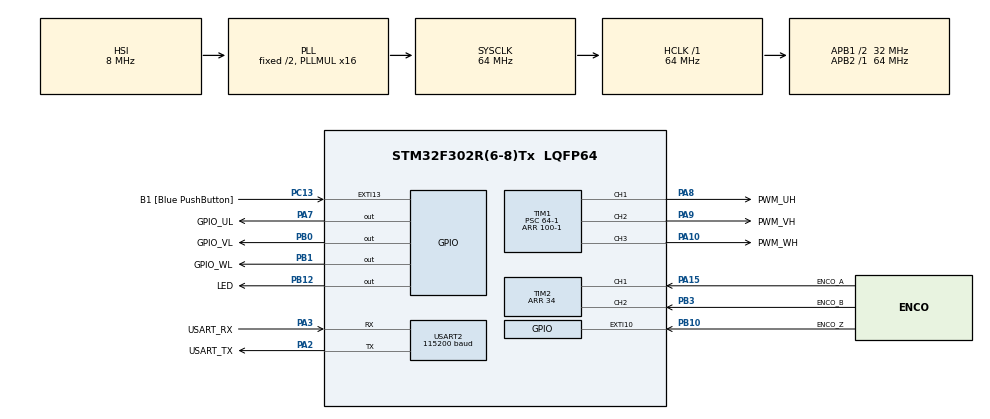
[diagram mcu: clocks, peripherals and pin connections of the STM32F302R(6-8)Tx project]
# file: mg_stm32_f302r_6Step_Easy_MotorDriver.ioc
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Mcu.Family=STM32F3
Mcu.Name=STM32F302R(6-8)Tx
Mcu.Package=LQFP64
NVIC.EXTI15_10_IRQn=true\:0\:0\:false\:false\:true\:true\:true\:true
NVIC.PriorityGroup=NVIC_PRIORITYGROUP_0
NVIC.TIM2_IRQn=true\:0\:0\:false\:false\:true\:true\:true\:true
NVIC.USART2_IRQn=true\:0\:0\:false\:false\:true\:true\:true\:true
PA10.GPIO_Label=PWM_WH
PA10.Signal=S_TIM1_CH3
PA13.GPIO_Label=TMS
PA13.Signal=SYS_JTMS-SWDIO
PA14.GPIO_Label=TCK
PA14.Signal=SYS_JTCK-SWCLK
PA15.GPIO_Label=ENCO_A
PA15.Signal=S_TIM2_CH1_ETR
PA2.GPIO_Label=USART_TX
PA2.GPIO_Mode=GPIO_MODE_AF_PP
PA2.GPIO_PuPd=GPIO_NOPULL
PA2.GPIO_Speed=GPIO_SPEED_FREQ_LOW
PA2.Mode=Asynchronous
PA2.Signal=USART2_TX
PA3.GPIO_Label=USART_RX
PA3.GPIO_Mode=GPIO_MODE_AF_PP
PA3.GPIO_PuPd=GPIO_NOPULL
PA3.GPIO_Speed=GPIO_SPEED_FREQ_LOW
PA3.Mode=Asynchronous
PA3.Signal=USART2_RX
PA7.GPIO_Label=GPIO_UL
PA7.Signal=GPIO_Output
PA8.GPIO_Label=PWM_UH
PA8.Signal=S_TIM1_CH1
PA9.GPIO_Label=PWM_VH
PA9.Signal=S_TIM1_CH2
PB0.GPIO_Label=GPIO_VL
PB0.Signal=GPIO_Output
PB1.GPIO_Label=GPIO_WL
PB1.Signal=GPIO_Output
PB10.GPIO_Label=ENCO_Z
PB10.Signal=GPXTI10
PB12.GPIO_Label=LED
PB12.Signal=GPIO_Output
PB3.GPIO_Label=ENCO_B
PB3.Signal=S_TIM2_CH2
PC13.GPIO_Label=B1 [Blue PushButton]
PC13.GPIO_ModeDefaultEXTI=GPIO_MODE_IT_FALLING
PC13.Signal=GPXTI13
ProjectManager.HeapSize=0x200
ProjectManager.StackSize=0x400
ProjectManager.TargetToolchain=STM32CubeIDE
RCC.AHBFreq_Value=64000000
RCC.APB1CLKDivider=RCC_HCLK_DIV2
RCC.APB1Freq_Value=32000000
RCC.APB1TimFreq_Value=64000000
RCC.APB2Freq_Value=64000000
RCC.APB2TimFreq_Value=64000000
RCC.CortexFreq_Value=64000000
RCC.HCLKFreq_Value=64000000
RCC.HSE_VALUE=8000000
RCC.HSI_VALUE=8000000
RCC.LSE_VALUE=32768
RCC.PLLM=8
RCC.PLLMUL=RCC_PLL_MUL16
RCC.PLLN=336
RCC.PLLP=RCC_PLLP_DIV4
RCC.PLLQ=7
RCC.RCC_PLLsource_Clock_Source_FROM_HSE=RCC_HSE_PREDIV_DIV2
RCC.SYSCLKFreq_VALUE=64000000
RCC.SYSCLKSourceVirtual=RCC_SYSCLKSOURCE_PLLCLK
RCC.USBFreq_Value=64000000
SH.S_TIM1_CH1.0=TIM1_CH1,PWM Generation1 CH1
SH.S_TIM1_CH2.0=TIM1_CH2,PWM Generation2 CH2
SH.S_TIM1_CH3.0=TIM1_CH3,PWM Generation3 CH3
SH.S_TIM2_CH1_ETR.0=TIM2_CH1,Encoder_Interface
SH.S_TIM2_CH2.0=TIM2_CH2,Encoder_Interface
TIM1.Channel-PWM\ Generation1\ CH1=TIM_CHANNEL_1
TIM1.Channel-PWM\ Generation2\ CH2=TIM_CHANNEL_2
TIM1.Channel-PWM\ Generation3\ CH3=TIM_CHANNEL_3
TIM1.Period=100-1
TIM1.Prescaler=64-1
TIM2.Period=34
USART2.BaudRate=115200
USART2.VirtualMode-Asynchronous=VM_ASYNC
board=NUCLEO-F302R8

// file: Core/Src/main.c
/* USER CODE BEGIN Header */
/**
  ******************************************************************************
  * @file           : main.c
  * @brief          : Main program body
  ******************************************************************************
  * @attention
  *
  * Copyright (c) 2025 STMicroelectronics.
  * All rights reserved.
  *
  * This software is licensed under terms that can be found in the LICENSE file
  * in the root directory of this software component.
  * If no LICENSE file comes with this software, it is provided AS-IS.
  *
  ******************************************************************************
  */
/* USER CODE END Header */
#include "main.h"

/* USER CODE BEGIN Includes */
#include "app.h"

/* USER CODE END Includes */

TIM_HandleTypeDef htim1;
TIM_HandleTypeDef htim2;

UART_HandleTypeDef huart2;

void SystemClock_Config(void);
static void MX_GPIO_Init(void);
static void MX_TIM1_Init(void);
static void MX_TIM2_Init(void);
static void MX_USART2_UART_Init(void);

int main(void)
{

  /* MCU Configuration--------------------------------------------------------*/

  /* Reset of all peripherals, Initializes the Flash interface and the Systick. */
  HAL_Init();

  /* Configure the system clock */
  SystemClock_Config();

  /* Initialize all configured peripherals */
  MX_GPIO_Init();
  MX_TIM1_Init();
  MX_TIM2_Init();
  MX_USART2_UART_Init();
  /* USER CODE BEGIN 2 */
  init_app();

  /* USER CODE END 2 */

  /* Infinite loop */
  while (1)
  {

  }
}

void SystemClock_Config(void)
{
  RCC_OscInitTypeDef RCC_OscInitStruct = {0};
  RCC_ClkInitTypeDef RCC_ClkInitStruct = {0};
  RCC_PeriphCLKInitTypeDef PeriphClkInit = {0};

  /** Initializes the RCC Oscillators according to the specified parameters
  * in the RCC_OscInitTypeDef structure.
  */
  RCC_OscInitStruct.OscillatorType = RCC_OSCILLATORTYPE_HSI;
  RCC_OscInitStruct.HSIState = RCC_HSI_ON;
  RCC_OscInitStruct.HSICalibrationValue = RCC_HSICALIBRATION_DEFAULT;
  RCC_OscInitStruct.PLL.PLLState = RCC_PLL_ON;
  RCC_OscInitStruct.PLL.PLLSource = RCC_PLLSOURCE_HSI;
  RCC_OscInitStruct.PLL.PLLMUL = RCC_PLL_MUL16;
  if (HAL_RCC_OscConfig(&RCC_OscInitStruct) != HAL_OK)
  {
    Error_Handler();
  }

  /** Initializes the CPU, AHB and APB buses clocks
  */
  RCC_ClkInitStruct.ClockType = RCC_CLOCKTYPE_HCLK|RCC_CLOCKTYPE_SYSCLK
                              |RCC_CLOCKTYPE_PCLK1|RCC_CLOCKTYPE_PCLK2;
  RCC_ClkInitStruct.SYSCLKSource = RCC_SYSCLKSOURCE_PLLCLK;
  RCC_ClkInitStruct.AHBCLKDivider = RCC_SYSCLK_DIV1;
  RCC_ClkInitStruct.APB1CLKDivider = RCC_HCLK_DIV2;
  RCC_ClkInitStruct.APB2CLKDivider = RCC_HCLK_DIV1;

  if (HAL_RCC_ClockConfig(&RCC_ClkInitStruct, FLASH_LATENCY_2) != HAL_OK)
  {
    Error_Handler();
  }
  PeriphClkInit.PeriphClockSelection = RCC_PERIPHCLK_TIM1;
  PeriphClkInit.Tim1ClockSelection = RCC_TIM1CLK_HCLK;
  if (HAL_RCCEx_PeriphCLKConfig(&PeriphClkInit) != HAL_OK)
  {
    Error_Handler();
  }
}

static void MX_TIM1_Init(void)
{

  TIM_MasterConfigTypeDef sMasterConfig = {0};
  TIM_OC_InitTypeDef sConfigOC = {0};
  TIM_BreakDeadTimeConfigTypeDef sBreakDeadTimeConfig = {0};

  htim1.Instance = TIM1;
  htim1.Init.Prescaler = 64-1;
  htim1.Init.CounterMode = TIM_COUNTERMODE_UP;
  htim1.Init.Period = 100-1;
  htim1.Init.ClockDivision = TIM_CLOCKDIVISION_DIV1;
  htim1.Init.RepetitionCounter = 0;
  htim1.Init.AutoReloadPreload = TIM_AUTORELOAD_PRELOAD_DISABLE;
  if (HAL_TIM_PWM_Init(&htim1) != HAL_OK)
  {
    Error_Handler();
  }
  sMasterConfig.MasterOutputTrigger = TIM_TRGO_RESET;
  sMasterConfig.MasterOutputTrigger2 = TIM_TRGO2_RESET;
  sMasterConfig.MasterSlaveMode = TIM_MASTERSLAVEMODE_DISABLE;
  if (HAL_TIMEx_MasterConfigSynchronization(&htim1, &sMasterConfig) != HAL_OK)
  {
    Error_Handler();
  }
  sConfigOC.OCMode = TIM_OCMODE_PWM1;
  sConfigOC.Pulse = 0;
  sConfigOC.OCPolarity = TIM_OCPOLARITY_HIGH;
  sConfigOC.OCNPolarity = TIM_OCNPOLARITY_HIGH;
  sConfigOC.OCFastMode = TIM_OCFAST_DISABLE;
  sConfigOC.OCIdleState = TIM_OCIDLESTATE_RESET;
  sConfigOC.OCNIdleState = TIM_OCNIDLESTATE_RESET;
  if (HAL_TIM_PWM_ConfigChannel(&htim1, &sConfigOC, TIM_CHANNEL_1) != HAL_OK)
  {
    Error_Handler();
  }
  if (HAL_TIM_PWM_ConfigChannel(&htim1, &sConfigOC, TIM_CHANNEL_2) != HAL_OK)
  {
    Error_Handler();
  }
  if (HAL_TIM_PWM_ConfigChannel(&htim1, &sConfigOC, TIM_CHANNEL_3) != HAL_OK)
  {
    Error_Handler();
  }
  sBreakDeadTimeConfig.OffStateRunMode = TIM_OSSR_DISABLE;
  sBreakDeadTimeConfig.OffStateIDLEMode = TIM_OSSI_DISABLE;
  sBreakDeadTimeConfig.LockLevel = TIM_LOCKLEVEL_OFF;
  sBreakDeadTimeConfig.DeadTime = 0;
  sBreakDeadTimeConfig.BreakState = TIM_BREAK_DISABLE;
  sBreakDeadTimeConfig.BreakPolarity = TIM_BREAKPOLARITY_HIGH;
  sBreakDeadTimeConfig.BreakFilter = 0;
  sBreakDeadTimeConfig.Break2State = TIM_BREAK2_DISABLE;
  sBreakDeadTimeConfig.Break2Polarity = TIM_BREAK2POLARITY_HIGH;
  sBreakDeadTimeConfig.Break2Filter = 0;
  sBreakDeadTimeConfig.AutomaticOutput = TIM_AUTOMATICOUTPUT_DISABLE;
  if (HAL_TIMEx_ConfigBreakDeadTime(&htim1, &sBreakDeadTimeConfig) != HAL_OK)
  {
    Error_Handler();
  }
  HAL_TIM_MspPostInit(&htim1);

}

static void MX_TIM2_Init(void)
{

  TIM_Encoder_InitTypeDef sConfig = {0};
  TIM_MasterConfigTypeDef sMasterConfig = {0};

  htim2.Instance = TIM2;
  htim2.Init.Prescaler = 0;
  htim2.Init.CounterMode = TIM_COUNTERMODE_UP;
  htim2.Init.Period = 34;
  htim2.Init.ClockDivision = TIM_CLOCKDIVISION_DIV1;
  htim2.Init.AutoReloadPreload = TIM_AUTORELOAD_PRELOAD_DISABLE;
  sConfig.EncoderMode = TIM_ENCODERMODE_TI1;
  sConfig.IC1Polarity = TIM_ICPOLARITY_RISING;
  sConfig.IC1Selection = TIM_ICSELECTION_DIRECTTI;
  sConfig.IC1Prescaler = TIM_ICPSC_DIV1;
  sConfig.IC1Filter = 0;
  sConfig.IC2Polarity = TIM_ICPOLARITY_RISING;
  sConfig.IC2Selection = TIM_ICSELECTION_DIRECTTI;
  sConfig.IC2Prescaler = TIM_ICPSC_DIV1;
  sConfig.IC2Filter = 0;
  if (HAL_TIM_Encoder_Init(&htim2, &sConfig) != HAL_OK)
  {
    Error_Handler();
  }
  sMasterConfig.MasterOutputTrigger = TIM_TRGO_RESET;
  sMasterConfig.MasterSlaveMode = TIM_MASTERSLAVEMODE_DISABLE;
  if (HAL_TIMEx_MasterConfigSynchronization(&htim2, &sMasterConfig) != HAL_OK)
  {
    Error_Handler();
  }

}

static void MX_USART2_UART_Init(void)
{

  huart2.Instance = USART2;
  huart2.Init.BaudRate = 115200;
  huart2.Init.WordLength = UART_WORDLENGTH_8B;
  huart2.Init.StopBits = UART_STOPBITS_1;
  huart2.Init.Parity = UART_PARITY_NONE;
  huart2.Init.Mode = UART_MODE_TX_RX;
  huart2.Init.HwFlowCtl = UART_HWCONTROL_NONE;
  huart2.Init.OverSampling = UART_OVERSAMPLING_16;
  huart2.Init.OneBitSampling = UART_ONE_BIT_SAMPLE_DISABLE;
  huart2.AdvancedInit.AdvFeatureInit = UART_ADVFEATURE_NO_INIT;
  if (HAL_UART_Init(&huart2) != HAL_OK)
  {
    Error_Handler();
  }

}

static void MX_GPIO_Init(void)
{
  GPIO_InitTypeDef GPIO_InitStruct = {0};

  /* GPIO Ports Clock Enable */
  __HAL_RCC_GPIOC_CLK_ENABLE();
  __HAL_RCC_GPIOA_CLK_ENABLE();
  __HAL_RCC_GPIOB_CLK_ENABLE();

  /*Configure GPIO pin Output Level */
  HAL_GPIO_WritePin(GPIO_UL_GPIO_Port, GPIO_UL_Pin, GPIO_PIN_RESET);

  /*Configure GPIO pin Output Level */
  HAL_GPIO_WritePin(GPIOB, GPIO_VL_Pin|GPIO_WL_Pin|LED_Pin, GPIO_PIN_RESET);

  /*Configure GPIO pin : B1_Pin */
  GPIO_InitStruct.Pin = B1_Pin;
  GPIO_InitStruct.Mode = GPIO_MODE_IT_FALLING;
  GPIO_InitStruct.Pull = GPIO_NOPULL;
  HAL_GPIO_Init(B1_GPIO_Port, &GPIO_InitStruct);

  /*Configure GPIO pin : GPIO_UL_Pin */
  GPIO_InitStruct.Pin = GPIO_UL_Pin;
  GPIO_InitStruct.Mode = GPIO_MODE_OUTPUT_PP;
  GPIO_InitStruct.Pull = GPIO_NOPULL;
  GPIO_InitStruct.Speed = GPIO_SPEED_FREQ_LOW;
  HAL_GPIO_Init(GPIO_UL_GPIO_Port, &GPIO_InitStruct);

  /*Configure GPIO pins : GPIO_VL_Pin GPIO_WL_Pin LED_Pin */
  GPIO_InitStruct.Pin = GPIO_VL_Pin|GPIO_WL_Pin|LED_Pin;
  GPIO_InitStruct.Mode = GPIO_MODE_OUTPUT_PP;
  GPIO_InitStruct.Pull = GPIO_NOPULL;
  GPIO_InitStruct.Speed = GPIO_SPEED_FREQ_LOW;
  HAL_GPIO_Init(GPIOB, &GPIO_InitStruct);

  /*Configure GPIO pin : ENCO_Z_Pin */
  GPIO_InitStruct.Pin = ENCO_Z_Pin;
  GPIO_InitStruct.Mode = GPIO_MODE_IT_RISING;
  GPIO_InitStruct.Pull = GPIO_NOPULL;
  HAL_GPIO_Init(ENCO_Z_GPIO_Port, &GPIO_InitStruct);

  /* EXTI interrupt init*/
  HAL_NVIC_SetPriority(EXTI15_10_IRQn, 0, 0);
  HAL_NVIC_EnableIRQ(EXTI15_10_IRQn);

}

void Error_Handler(void)
{
  __disable_irq();
  while (1)
  {
  }
}
